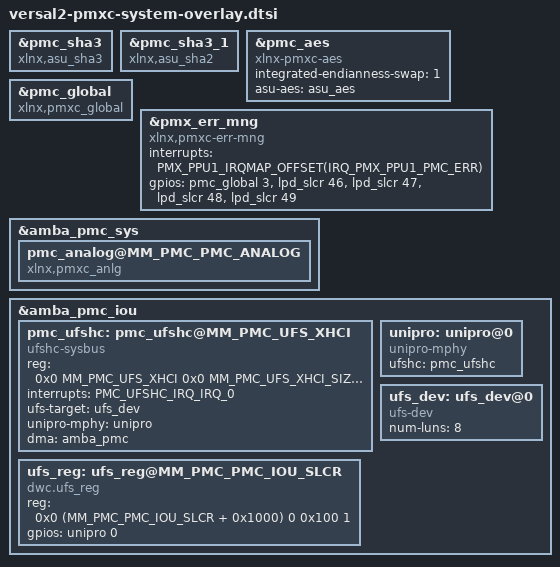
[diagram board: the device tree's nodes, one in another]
/*
 * Versal Gen 2 PMXC System Overlay. This contains the overlay suitable
 * for the system parts (ARM instance) of the multi-arch PSX/PMCX
 * setup.
 *
 * Copyright (C) 2023, Advanced Micro Devices, Inc
 * All rights reserved.
 *
 * Redistribution and use in source and binary forms, with or without
 * modification, are permitted provided that the following conditions are met:
 *     * Redistributions of source code must retain the above copyright
 *       notice, this list of conditions and the following disclaimer.
 *     * Redistributions in binary form must reproduce the above copyright
 *       notice, this list of conditions and the following disclaimer in the
 *       documentation and/or other materials provided with the distribution.
 *     * Neither the name of the <organization> nor the
 *       names of its contributors may be used to endorse or promote products
 *       derived from this software without specific prior written permission.
 *
 * THIS SOFTWARE IS PROVIDED BY THE COPYRIGHT HOLDERS AND CONTRIBUTORS "AS IS" AND
 * ANY EXPRESS OR IMPLIED WARRANTIES, INCLUDING, BUT NOT LIMITED TO, THE IMPLIED
 * WARRANTIES OF MERCHANTABILITY AND FITNESS FOR A PARTICULAR PURPOSE ARE
 * DISCLAIMED. IN NO EVENT SHALL <COPYRIGHT HOLDER> BE LIABLE FOR ANY
 * DIRECT, INDIRECT, INCIDENTAL, SPECIAL, EXEMPLARY, OR CONSEQUENTIAL DAMAGES
 * (INCLUDING, BUT NOT LIMITED TO, PROCUREMENT OF SUBSTITUTE GOODS OR SERVICES;
 * LOSS OF USE, DATA, OR PROFITS; OR BUSINESS INTERRUPTION) HOWEVER CAUSED AND
 * ON ANY THEORY OF LIABILITY, WHETHER IN CONTRACT, STRICT LIABILITY, OR TORT
 * (INCLUDING NEGLIGENCE OR OTHERWISE) ARISING IN ANY WAY OUT OF THE USE OF THIS
 * SOFTWARE, EVEN IF ADVISED OF THE POSSIBILITY OF SUCH DAMAGE.
 */

/* The implementation of the hash accelerators changes from versal-net to
 * versal2.  This is reflected here.  */
&pmc_sha3 {
	compatible = "xlnx,asu_sha3";
};

&pmc_sha3_1 {
	compatible = "xlnx,asu_sha2";
};

/* versal2 AES wrapper has additional endianness swap after the DMA input and
 * before the DMA output.  */
&pmc_aes {
	integrated-endianness-swap = < 1 >;
};

&pmc_global {
	compatible = "xlnx,pmxc_global";
};

&pmx_err_mng {
	compatible = "xlnx,pmxc-err-mng";
	interrupts = <PMX_PPU1_IRQMAP_OFFSET(IRQ_PMX_PPU1_PMC_ERR)>;
	gpios = <&pmc_global 3
		 &lpd_slcr 46
		 &lpd_slcr 47
		 &lpd_slcr 48
		 &lpd_slcr 49>;
};

&pmc_aes {
	compatible = "xlnx-pmxc-aes";
	asu-aes = <&asu_aes>;
};

&amba_pmc_sys {
	pmc_analog@MM_PMC_PMC_ANALOG {
		compatible = "xlnx,pmxc_anlg";
	};
};

&amba_pmc_iou {
	pmc_ufshc: pmc_ufshc@MM_PMC_UFS_XHCI {
		compatible = "ufshc-sysbus";
		reg = <0x0 MM_PMC_UFS_XHCI 0x0 MM_PMC_UFS_XHCI_SIZE 0x0>;
		interrupts = <PMC_UFSHC_IRQ_IRQ_0>;
		ufs-target = <&ufs_dev>;
		unipro-mphy = <&unipro>;
		dma = <&amba_pmc>;
	};
	unipro: unipro@0 {
		compatible = "unipro-mphy";
		ufshc = <&pmc_ufshc>;
		#gpio-cells = <1>;
	};
	ufs_dev: ufs_dev@0 {
		compatible = "ufs-dev";
		num-luns = <8>;
	};
	ufs_reg: ufs_reg@MM_PMC_PMC_IOU_SLCR {
		compatible = "dwc.ufs_reg";
		reg = <0x0 (MM_PMC_PMC_IOU_SLCR + 0x1000) 0 0x100 1>;
		gpios = <&unipro 0>;
	};
};
